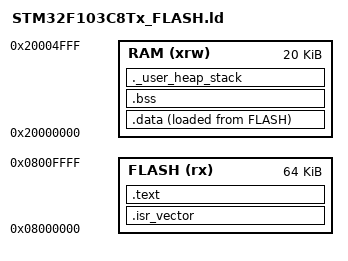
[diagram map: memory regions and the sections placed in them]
/* STM32F103C8T6: 64KB Flash, 20KB RAM */
MEMORY
{
  FLASH (rx)      : ORIGIN = 0x08000000, LENGTH = 64K
  RAM (xrw)       : ORIGIN = 0x20000000, LENGTH = 20K
}

/* ⚠️ 关键：定义 _estack 符号 */
_estack = ORIGIN(RAM) + LENGTH(RAM);

ENTRY(Reset_Handler)

SECTIONS
{
  /* ⚠️ 关键：向量表段定义 */
  .isr_vector :
  {
    . = ALIGN(4);
    KEEP(*(.isr_vector))
    . = ALIGN(4);
  } >FLASH

  .text :
  {
    . = ALIGN(4);
    *(.text)
    *(.text*)
    *(.rodata)
    *(.rodata*)
    . = ALIGN(4);
    _etext = .;
  } >FLASH

  .data :
  {
    . = ALIGN(4);
    _sdata = .;
    *(.data)
    *(.data*)
    . = ALIGN(4);
    _edata = .;
  } >RAM AT> FLASH

  _sidata = LOADADDR(.data);

  .bss :
  {
    . = ALIGN(4);
    _sbss = .;
    *(.bss)
    *(.bss*)
    *(COMMON)
    . = ALIGN(4);
    _ebss = .;
  } >RAM

  ._user_heap_stack :
  {
    . = ALIGN(8);
    PROVIDE(end = .);
    PROVIDE(_end = .);
    . = . + 0x200;
    . = . + 0x400;
    . = ALIGN(8);
  } >RAM

  /DISCARD/ :
  {
    *(.ARM.exidx*)
    *(.ARM.attributes*)
  }
}
